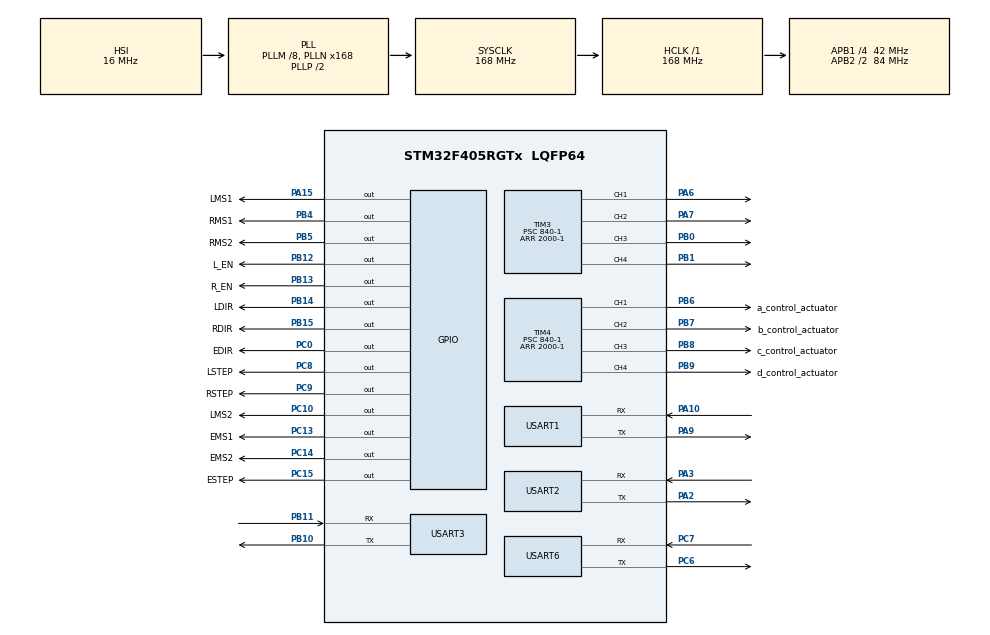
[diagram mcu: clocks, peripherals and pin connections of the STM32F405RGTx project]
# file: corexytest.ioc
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Dma.Request0=USART1_RX
Dma.Request1=USART1_TX
Dma.USART1_RX.0.Direction=DMA_PERIPH_TO_MEMORY
Dma.USART1_RX.0.FIFOMode=DMA_FIFOMODE_DISABLE
Dma.USART1_RX.0.Instance=DMA2_Stream2
Dma.USART1_RX.0.MemDataAlignment=DMA_MDATAALIGN_BYTE
Dma.USART1_RX.0.MemInc=DMA_MINC_ENABLE
Dma.USART1_RX.0.Mode=DMA_NORMAL
Dma.USART1_RX.0.PeriphDataAlignment=DMA_PDATAALIGN_BYTE
Dma.USART1_RX.0.PeriphInc=DMA_PINC_DISABLE
Dma.USART1_RX.0.Priority=DMA_PRIORITY_LOW
Dma.USART1_TX.1.Direction=DMA_MEMORY_TO_PERIPH
Dma.USART1_TX.1.FIFOMode=DMA_FIFOMODE_DISABLE
Dma.USART1_TX.1.Instance=DMA2_Stream7
Dma.USART1_TX.1.MemDataAlignment=DMA_MDATAALIGN_BYTE
Dma.USART1_TX.1.MemInc=DMA_MINC_ENABLE
Dma.USART1_TX.1.Mode=DMA_NORMAL
Dma.USART1_TX.1.PeriphDataAlignment=DMA_PDATAALIGN_BYTE
Dma.USART1_TX.1.PeriphInc=DMA_PINC_DISABLE
Dma.USART1_TX.1.Priority=DMA_PRIORITY_LOW
Mcu.Family=STM32F4
Mcu.Name=STM32F405RGTx
Mcu.Package=LQFP64
NVIC.DMA2_Stream2_IRQn=true\:0\:0\:false\:false\:true\:false\:true\:true
NVIC.DMA2_Stream7_IRQn=true\:0\:0\:false\:false\:true\:false\:true\:true
NVIC.PriorityGroup=NVIC_PRIORITYGROUP_4
NVIC.USART1_IRQn=true\:0\:0\:false\:false\:true\:true\:true\:true
PA10.Mode=Asynchronous
PA10.Signal=USART1_RX
PA13.Mode=Serial_Wire
PA13.Signal=SYS_JTMS-SWDIO
PA14.Mode=Serial_Wire
PA14.Signal=SYS_JTCK-SWCLK
PA15.GPIO_Label=LMS1
PA15.Signal=GPIO_Output
PA2.Mode=Asynchronous
PA2.Signal=USART2_TX
PA3.Mode=Asynchronous
PA3.Signal=USART2_RX
PA6.Signal=S_TIM3_CH1
PA7.Signal=S_TIM3_CH2
PA9.Mode=Asynchronous
PA9.Signal=USART1_TX
PB0.Signal=S_TIM3_CH3
PB1.Signal=S_TIM3_CH4
PB10.Mode=Asynchronous
PB10.Signal=USART3_TX
PB11.Mode=Asynchronous
PB11.Signal=USART3_RX
PB12.GPIO_Label=L_EN
PB12.Signal=GPIO_Output
PB13.GPIO_Label=R_EN
PB13.Signal=GPIO_Output
PB14.GPIO_Label=LDIR
PB14.Signal=GPIO_Output
PB15.GPIO_Label=RDIR
PB15.Signal=GPIO_Output
PB4.GPIO_Label=RMS1
PB4.Signal=GPIO_Output
PB5.GPIO_Label=RMS2
PB5.Signal=GPIO_Output
PB6.GPIO_Label=a_control_actuator
PB6.Signal=S_TIM4_CH1
PB7.GPIO_Label=b_control_actuator
PB7.Signal=S_TIM4_CH2
PB8.GPIO_Label=c_control_actuator
PB8.Signal=S_TIM4_CH3
PB9.GPIO_Label=d_control_actuator
PB9.Signal=S_TIM4_CH4
PC0.GPIO_Label=EDIR
PC0.Signal=GPIO_Output
PC10.GPIO_Label=LMS2
PC10.Signal=GPIO_Output
PC13-ANTI_TAMP.GPIO_Label=EMS1
PC13-ANTI_TAMP.Signal=GPIO_Output
PC14-OSC32_IN.GPIO_Label=EMS2
PC14-OSC32_IN.Signal=GPIO_Output
PC15-OSC32_OUT.GPIO_Label=ESTEP
PC15-OSC32_OUT.Signal=GPIO_Output
PC6.Mode=Asynchronous
PC6.Signal=USART6_TX
PC7.Mode=Asynchronous
PC7.Signal=USART6_RX
PC8.GPIO_Label=LSTEP
PC8.GPIO_Speed=GPIO_SPEED_FREQ_HIGH
PC8.PinState=GPIO_PIN_SET
PC8.Signal=GPIO_Output
PC9.GPIO_Label=RSTEP
PC9.Signal=GPIO_Output
PH0-OSC_IN.Mode=HSE-External-Oscillator
PH0-OSC_IN.Signal=RCC_OSC_IN
PH1-OSC_OUT.Mode=HSE-External-Oscillator
PH1-OSC_OUT.Signal=RCC_OSC_OUT
ProjectManager.HeapSize=0x200
ProjectManager.StackSize=0x400
ProjectManager.TargetToolchain=MDK-ARM V5.32
RCC.48MHZClocksFreq_Value=84000000
RCC.AHBFreq_Value=168000000
RCC.APB1CLKDivider=RCC_HCLK_DIV4
RCC.APB1Freq_Value=42000000
RCC.APB1TimFreq_Value=84000000
RCC.APB2CLKDivider=RCC_HCLK_DIV2
RCC.APB2Freq_Value=84000000
RCC.APB2TimFreq_Value=168000000
RCC.CortexFreq_Value=168000000
RCC.HCLKFreq_Value=168000000
RCC.HSE_VALUE=25000000
RCC.HSI_VALUE=16000000
RCC.LSE_VALUE=32768
RCC.PLLM=8
RCC.PLLN=168
RCC.SYSCLKFreq_VALUE=168000000
RCC.SYSCLKSource=RCC_SYSCLKSOURCE_PLLCLK
RCC.VCOOutputFreq_Value=336000000
SH.S_TIM3_CH1.0=TIM3_CH1,PWM Generation1 CH1
SH.S_TIM3_CH2.0=TIM3_CH2,PWM Generation2 CH2
SH.S_TIM3_CH3.0=TIM3_CH3,PWM Generation3 CH3
SH.S_TIM3_CH4.0=TIM3_CH4,PWM Generation4 CH4
SH.S_TIM4_CH1.0=TIM4_CH1,PWM Generation1 CH1
SH.S_TIM4_CH2.0=TIM4_CH2,PWM Generation2 CH2
SH.S_TIM4_CH3.0=TIM4_CH3,PWM Generation3 CH3
SH.S_TIM4_CH4.0=TIM4_CH4,PWM Generation4 CH4
TIM3.AutoReloadPreload=TIM_AUTORELOAD_PRELOAD_ENABLE
TIM3.Channel-PWM\ Generation1\ CH1=TIM_CHANNEL_1
TIM3.Channel-PWM\ Generation2\ CH2=TIM_CHANNEL_2
TIM3.Channel-PWM\ Generation3\ CH3=TIM_CHANNEL_3
TIM3.Channel-PWM\ Generation4\ CH4=TIM_CHANNEL_4
TIM3.Period=2000-1
TIM3.Prescaler=840-1
TIM4.AutoReloadPreload=TIM_AUTORELOAD_PRELOAD_ENABLE
TIM4.Channel-PWM\ Generation1\ CH1=TIM_CHANNEL_1
TIM4.Channel-PWM\ Generation2\ CH2=TIM_CHANNEL_2
TIM4.Channel-PWM\ Generation3\ CH3=TIM_CHANNEL_3
TIM4.Channel-PWM\ Generation4\ CH4=TIM_CHANNEL_4
TIM4.Period=2000-1
TIM4.Prescaler=840-1
USART1.VirtualMode=VM_ASYNC
USART2.VirtualMode=VM_ASYNC
USART3.VirtualMode=VM_ASYNC
USART6.VirtualMode=VM_ASYNC
VP_TIM3_VS_ClockSourceINT.Mode=Internal
VP_TIM4_VS_ClockSourceINT.Mode=Internal
VP_TIM5_VS_ClockSourceINT.Mode=Internal
board=custom

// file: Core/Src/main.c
/* USER CODE BEGIN Header */
/**
  ******************************************************************************
  * @file           : main.c
  * @brief          : Main program body
  ******************************************************************************
  * @attention
  *
  * Copyright (c) 2024 STMicroelectronics.
  * All rights reserved.
  *
  * This software is licensed under terms that can be found in the LICENSE file
  * in the root directory of this software component.
  * If no LICENSE file comes with this software, it is provided AS-IS.
  *
  ******************************************************************************
  */
/* USER CODE END Header */
#include "main.h"
#include "dma.h"
#include "tim.h"
#include "usart.h"
#include "gpio.h"

void SystemClock_Config(void);

int main(void)
{

  /* MCU Configuration--------------------------------------------------------*/

  /* Reset of all peripherals, Initializes the Flash interface and the Systick. */
  HAL_Init();

  /* Configure the system clock */
  SystemClock_Config();

  /* Initialize all configured peripherals */
  MX_GPIO_Init();
  MX_DMA_Init();
  MX_TIM3_Init();
  MX_TIM4_Init();
  MX_TIM5_Init();
  MX_USART1_UART_Init();
  MX_USART2_UART_Init();
  MX_USART3_UART_Init();
  MX_USART6_UART_Init();
  /* USER CODE BEGIN 2 */
HAL_TIM_PWM_Start(&htim4,TIM_CHANNEL_1);
HAL_TIM_PWM_Start(&htim4,TIM_CHANNEL_2);
HAL_TIM_PWM_Start(&htim4,TIM_CHANNEL_3);
HAL_TIM_PWM_Start(&htim4,TIM_CHANNEL_4);

int ca_a=50;  //50到250
int ca_b=50;
int ca_c=50;  //50到250
int ca_d=50;

// uint8_t test_data=0x05;
// __HAL_TIM_SET_COMPARE(&htim4,TIM_CHANNEL_1,200);//200最低，100最高

HAL_UARTEx_ReceiveToIdle_DMA(&huart1,rx_buf,BUFF_SIZE);

print_data();
  /* USER CODE END 2 */

  /* Infinite loop */
  while (1)
  {

    /* USER CODE BEGIN 3 */

 print_data();
  HAL_Delay(1000);
  }
  /* USER CODE END 3 */
}

void SystemClock_Config(void)
{
  RCC_OscInitTypeDef RCC_OscInitStruct = {0};
  RCC_ClkInitTypeDef RCC_ClkInitStruct = {0};

  /** Configure the main internal regulator output voltage
  */
  __HAL_RCC_PWR_CLK_ENABLE();
  __HAL_PWR_VOLTAGESCALING_CONFIG(PWR_REGULATOR_VOLTAGE_SCALE1);

  /** Initializes the RCC Oscillators according to the specified parameters
  * in the RCC_OscInitTypeDef structure.
  */
  RCC_OscInitStruct.OscillatorType = RCC_OSCILLATORTYPE_HSI;
  RCC_OscInitStruct.HSIState = RCC_HSI_ON;
  RCC_OscInitStruct.HSICalibrationValue = RCC_HSICALIBRATION_DEFAULT;
  RCC_OscInitStruct.PLL.PLLState = RCC_PLL_ON;
  RCC_OscInitStruct.PLL.PLLSource = RCC_PLLSOURCE_HSI;
  RCC_OscInitStruct.PLL.PLLM = 8;
  RCC_OscInitStruct.PLL.PLLN = 168;
  RCC_OscInitStruct.PLL.PLLP = RCC_PLLP_DIV2;
  RCC_OscInitStruct.PLL.PLLQ = 4;
  if (HAL_RCC_OscConfig(&RCC_OscInitStruct) != HAL_OK)
  {
    Error_Handler();
  }

  /** Initializes the CPU, AHB and APB buses clocks
  */
  RCC_ClkInitStruct.ClockType = RCC_CLOCKTYPE_HCLK|RCC_CLOCKTYPE_SYSCLK
                              |RCC_CLOCKTYPE_PCLK1|RCC_CLOCKTYPE_PCLK2;
  RCC_ClkInitStruct.SYSCLKSource = RCC_SYSCLKSOURCE_PLLCLK;
  RCC_ClkInitStruct.AHBCLKDivider = RCC_SYSCLK_DIV1;
  RCC_ClkInitStruct.APB1CLKDivider = RCC_HCLK_DIV4;
  RCC_ClkInitStruct.APB2CLKDivider = RCC_HCLK_DIV2;

  if (HAL_RCC_ClockConfig(&RCC_ClkInitStruct, FLASH_LATENCY_5) != HAL_OK)
  {
    Error_Handler();
  }
}

void Error_Handler(void)
{
  __disable_irq();
  while (1)
  {
  }
}
